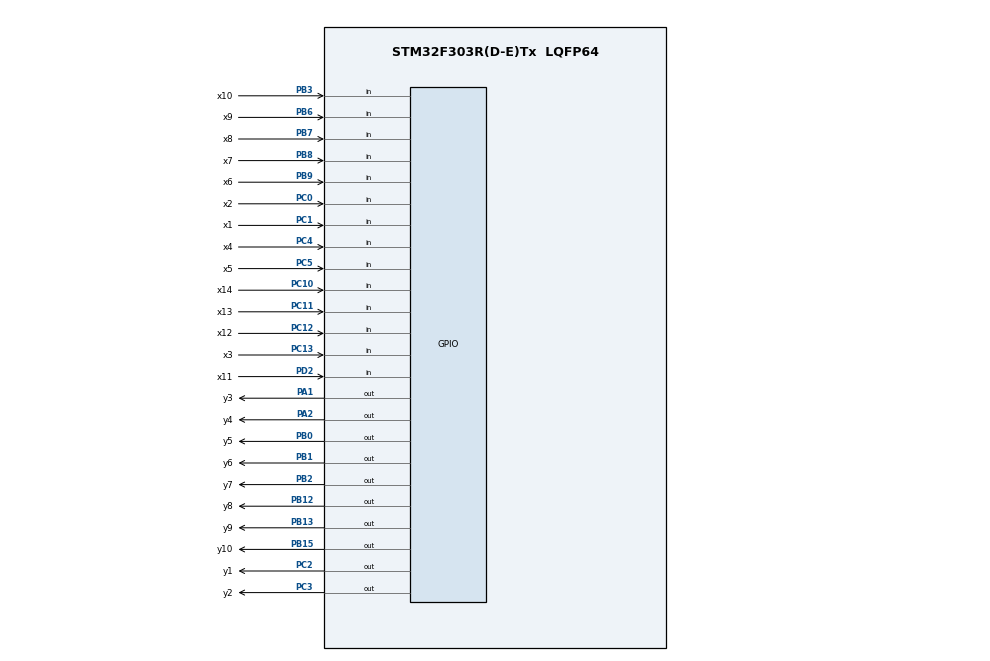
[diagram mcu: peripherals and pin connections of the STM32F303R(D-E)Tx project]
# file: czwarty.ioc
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Mcu.Family=STM32F3
Mcu.Name=STM32F303R(D-E)Tx
Mcu.Package=LQFP64
NVIC.PriorityGroup=NVIC_PRIORITYGROUP_4
PA0.Signal=S_TIM2_CH1_ETR
PA1.GPIO_Label=y3
PA1.Signal=GPIO_Output
PA2.GPIO_Label=y4
PA2.Signal=GPIO_Output
PB0.GPIO_Label=y5
PB0.Signal=GPIO_Output
PB1.GPIO_Label=y6
PB1.Signal=GPIO_Output
PB12.GPIO_Label=y8
PB12.Signal=GPIO_Output
PB13.GPIO_Label=y9
PB13.Signal=GPIO_Output
PB15.GPIO_Label=y10
PB15.Signal=GPIO_Output
PB2.GPIO_Label=y7
PB2.Signal=GPIO_Output
PB3.GPIO_Label=x10
PB3.Signal=GPIO_Input
PB4.Signal=S_TIM16_CH1
PB5.Signal=S_TIM17_CH1
PB6.GPIO_Label=x9
PB6.Signal=GPIO_Input
PB7.GPIO_Label=x8
PB7.Signal=GPIO_Input
PB8.GPIO_Label=x7
PB8.Signal=GPIO_Input
PB9.GPIO_Label=x6
PB9.Signal=GPIO_Input
PC0.GPIO_Label=x2
PC0.Signal=GPIO_Input
PC1.GPIO_Label=x1
PC1.Signal=GPIO_Input
PC10.GPIO_Label=x14
PC10.Signal=GPIO_Input
PC11.GPIO_Label=x13
PC11.Signal=GPIO_Input
PC12.GPIO_Label=x12
PC12.Signal=GPIO_Input
PC13.GPIO_Label=x3
PC13.Signal=GPIO_Input
PC14-OSC32_IN.Mode=LSE-External-Oscillator
PC14-OSC32_IN.Signal=RCC_OSC32_IN
PC15-OSC32_OUT.Mode=LSE-External-Oscillator
PC15-OSC32_OUT.Signal=RCC_OSC32_OUT
PC2.GPIO_Label=y1
PC2.Signal=GPIO_Output
PC3.GPIO_Label=y2
PC3.Signal=GPIO_Output
PC4.GPIO_Label=x4
PC4.Signal=GPIO_Input
PC5.GPIO_Label=x5
PC5.Signal=GPIO_Input
PC8.Signal=S_TIM8_CH3
PD2.GPIO_Label=x11
PD2.Signal=GPIO_Input
PF0-OSC_IN.Mode=HSE-External-Oscillator
PF0-OSC_IN.Signal=RCC_OSC_IN
PF1-OSC_OUT.Mode=HSE-External-Oscillator
PF1-OSC_OUT.Signal=RCC_OSC_OUT
ProjectManager.HeapSize=0x200
ProjectManager.StackSize=0x400
ProjectManager.TargetToolchain=TrueSTUDIO
RCC.AHBFreq_Value=72000000
RCC.APB1CLKDivider=RCC_HCLK_DIV2
RCC.APB1Freq_Value=36000000
RCC.APB1TimFreq_Value=72000000
RCC.APB2Freq_Value=72000000
RCC.APB2TimFreq_Value=72000000
RCC.CortexFreq_Value=72000000
RCC.HCLKFreq_Value=72000000
RCC.HSE_VALUE=8000000
RCC.HSI_VALUE=8000000
RCC.PLLMUL=RCC_PLL_MUL9
RCC.PLLSourceVirtual=RCC_PLLSOURCE_HSE
RCC.SYSCLKFreq_VALUE=72000000
RCC.SYSCLKSourceVirtual=RCC_SYSCLKSOURCE_PLLCLK
RCC.USBFreq_Value=72000000
SH.S_TIM16_CH1.0=TIM16_CH1
SH.S_TIM17_CH1.0=TIM17_CH1
SH.S_TIM2_CH1_ETR.0=TIM2_CH1
SH.S_TIM8_CH3.0=TIM8_CH3
board=czwarty

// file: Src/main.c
/**
  ******************************************************************************
  * @file           : main.c
  * @brief          : Main program body
  ******************************************************************************
  ** This notice applies to any and all portions of this file
  * that are not between comment pairs USER CODE BEGIN and
  * USER CODE END. Other portions of this file, whether
  * inserted by the user or by software development tools
  * are owned by their respective copyright owners.
  *
  * COPYRIGHT(c) 2019 STMicroelectronics
  *
  * Redistribution and use in source and binary forms, with or without modification,
  * are permitted provided that the following conditions are met:
  *   1. Redistributions of source code must retain the above copyright notice,
  *      this list of conditions and the following disclaimer.
  *   2. Redistributions in binary form must reproduce the above copyright notice,
  *      this list of conditions and the following disclaimer in the documentation
  *      and/or other materials provided with the distribution.
  *   3. Neither the name of STMicroelectronics nor the names of its contributors
  *      may be used to endorse or promote products derived from this software
  *      without specific prior written permission.
  *
  * THIS SOFTWARE IS PROVIDED BY THE COPYRIGHT HOLDERS AND CONTRIBUTORS "AS IS"
  * AND ANY EXPRESS OR IMPLIED WARRANTIES, INCLUDING, BUT NOT LIMITED TO, THE
  * IMPLIED WARRANTIES OF MERCHANTABILITY AND FITNESS FOR A PARTICULAR PURPOSE ARE
  * DISCLAIMED. IN NO EVENT SHALL THE COPYRIGHT HOLDER OR CONTRIBUTORS BE LIABLE
  * FOR ANY DIRECT, INDIRECT, INCIDENTAL, SPECIAL, EXEMPLARY, OR CONSEQUENTIAL
  * DAMAGES (INCLUDING, BUT NOT LIMITED TO, PROCUREMENT OF SUBSTITUTE GOODS OR
  * SERVICES; LOSS OF USE, DATA, OR PROFITS; OR BUSINESS INTERRUPTION) HOWEVER
  * CAUSED AND ON ANY THEORY OF LIABILITY, WHETHER IN CONTRACT, STRICT LIABILITY,
  * OR TORT (INCLUDING NEGLIGENCE OR OTHERWISE) ARISING IN ANY WAY OUT OF THE USE
  * OF THIS SOFTWARE, EVEN IF ADVISED OF THE POSSIBILITY OF SUCH DAMAGE.
  *
  ******************************************************************************
  */
#include "main.h"

/* USER CODE BEGIN PV */
/* Private variables ---------------------------------------------------------*/

/* USER CODE END PV */

static void LL_Init(void);
void SystemClock_Config(void);
static void MX_GPIO_Init(void);

/* USER CODE BEGIN PFP */
/* Private function prototypes -----------------------------------------------*/

/* USER CODE END PFP */

int main(void)
{

  /* MCU Configuration----------------------------------------------------------*/

  /* Reset of all peripherals, Initializes the Flash interface and the Systick. */
  LL_Init();

  /* Configure the system clock */
  SystemClock_Config();

  /* Initialize all configured peripherals */
  MX_GPIO_Init();

  /* Infinite loop */
  while (1)
  {

  /* USER CODE BEGIN 3 */
	  LL_GPIO_SetOutputPin(y1_GPIO_Port,y1_Pin);// zapalenie diody
	  LL_GPIO_SetOutputPin(y2_GPIO_Port,y2_Pin);
	          //delay(400);
	           //LL_GPIO_ResetOutputPin(y9_GPIO_Port,y9_Pin); // zgaszenie diody
	          //Delay(400);

  }
  /* USER CODE END 3 */

}

static void LL_Init(void)
{

  LL_APB2_GRP1_EnableClock(LL_APB2_GRP1_PERIPH_SYSCFG);

  NVIC_SetPriorityGrouping(NVIC_PRIORITYGROUP_4);

  /* System interrupt init*/
  /* MemoryManagement_IRQn interrupt configuration */
  NVIC_SetPriority(MemoryManagement_IRQn, NVIC_EncodePriority(NVIC_GetPriorityGrouping(),0, 0));
  /* BusFault_IRQn interrupt configuration */
  NVIC_SetPriority(BusFault_IRQn, NVIC_EncodePriority(NVIC_GetPriorityGrouping(),0, 0));
  /* UsageFault_IRQn interrupt configuration */
  NVIC_SetPriority(UsageFault_IRQn, NVIC_EncodePriority(NVIC_GetPriorityGrouping(),0, 0));
  /* SVCall_IRQn interrupt configuration */
  NVIC_SetPriority(SVCall_IRQn, NVIC_EncodePriority(NVIC_GetPriorityGrouping(),0, 0));
  /* DebugMonitor_IRQn interrupt configuration */
  NVIC_SetPriority(DebugMonitor_IRQn, NVIC_EncodePriority(NVIC_GetPriorityGrouping(),0, 0));
  /* PendSV_IRQn interrupt configuration */
  NVIC_SetPriority(PendSV_IRQn, NVIC_EncodePriority(NVIC_GetPriorityGrouping(),0, 0));
  /* SysTick_IRQn interrupt configuration */
  NVIC_SetPriority(SysTick_IRQn, NVIC_EncodePriority(NVIC_GetPriorityGrouping(),0, 0));

}

void SystemClock_Config(void)
{

  LL_FLASH_SetLatency(LL_FLASH_LATENCY_2);

   if(LL_FLASH_GetLatency() != LL_FLASH_LATENCY_2)
  {
  Error_Handler();
  }
  LL_RCC_HSE_Enable();

   /* Wait till HSE is ready */
  while(LL_RCC_HSE_IsReady() != 1)
  {

  }
  LL_RCC_PLL_ConfigDomain_SYS(LL_RCC_PLLSOURCE_HSE, LL_RCC_PLL_MUL_9, LL_RCC_PREDIV_DIV_1);

  LL_RCC_PLL_Enable();

   /* Wait till PLL is ready */
  while(LL_RCC_PLL_IsReady() != 1)
  {

  }
  LL_RCC_SetAHBPrescaler(LL_RCC_SYSCLK_DIV_1);

  LL_RCC_SetAPB1Prescaler(LL_RCC_APB1_DIV_2);

  LL_RCC_SetAPB2Prescaler(LL_RCC_APB1_DIV_1);

  LL_RCC_SetSysClkSource(LL_RCC_SYS_CLKSOURCE_PLL);

   /* Wait till System clock is ready */
  while(LL_RCC_GetSysClkSource() != LL_RCC_SYS_CLKSOURCE_STATUS_PLL)
  {

  }
  LL_Init1msTick(72000000);

  LL_SYSTICK_SetClkSource(LL_SYSTICK_CLKSOURCE_HCLK);

  LL_SetSystemCoreClock(72000000);

  /* SysTick_IRQn interrupt configuration */
  NVIC_SetPriority(SysTick_IRQn, NVIC_EncodePriority(NVIC_GetPriorityGrouping(),0, 0));
}

/** Configure pins as
        * Analog
        * Input
        * Output
        * EVENT_OUT
        * EXTI
     PA0   ------> S_TIM2_CH1_ETR
     PC8   ------> S_TIM8_CH3
     PB4   ------> S_TIM16_CH1
     PB5   ------> S_TIM17_CH1
*/
static void MX_GPIO_Init(void)
{

  LL_GPIO_InitTypeDef GPIO_InitStruct;

  /* GPIO Ports Clock Enable */
  LL_AHB1_GRP1_EnableClock(LL_AHB1_GRP1_PERIPH_GPIOC);
  LL_AHB1_GRP1_EnableClock(LL_AHB1_GRP1_PERIPH_GPIOF);
  LL_AHB1_GRP1_EnableClock(LL_AHB1_GRP1_PERIPH_GPIOA);
  LL_AHB1_GRP1_EnableClock(LL_AHB1_GRP1_PERIPH_GPIOB);
  LL_AHB1_GRP1_EnableClock(LL_AHB1_GRP1_PERIPH_GPIOD);

  /**/
  LL_GPIO_ResetOutputPin(GPIOC, y1_Pin|y2_Pin);

  /**/
  LL_GPIO_ResetOutputPin(GPIOA, y3_Pin|y4_Pin);

  /**/
  LL_GPIO_ResetOutputPin(GPIOB, y5_Pin|y6_Pin|y7_Pin|y8_Pin
                          |y9_Pin|y10_Pin);

  /**/
  GPIO_InitStruct.Pin = x3_Pin|x2_Pin|x1_Pin|x4_Pin
                          |x5_Pin|x14_Pin|x13_Pin|x12_Pin;
  GPIO_InitStruct.Mode = LL_GPIO_MODE_INPUT;
  GPIO_InitStruct.Pull = LL_GPIO_PULL_NO;
  LL_GPIO_Init(GPIOC, &GPIO_InitStruct);

  /**/
  GPIO_InitStruct.Pin = y1_Pin|y2_Pin;
  GPIO_InitStruct.Mode = LL_GPIO_MODE_OUTPUT;
  GPIO_InitStruct.Speed = LL_GPIO_SPEED_FREQ_LOW;
  GPIO_InitStruct.OutputType = LL_GPIO_OUTPUT_PUSHPULL;
  GPIO_InitStruct.Pull = LL_GPIO_PULL_NO;
  LL_GPIO_Init(GPIOC, &GPIO_InitStruct);

  /**/
  GPIO_InitStruct.Pin = LL_GPIO_PIN_0;
  GPIO_InitStruct.Mode = LL_GPIO_MODE_ALTERNATE;
  GPIO_InitStruct.Speed = LL_GPIO_SPEED_FREQ_LOW;
  GPIO_InitStruct.OutputType = LL_GPIO_OUTPUT_PUSHPULL;
  GPIO_InitStruct.Pull = LL_GPIO_PULL_NO;
  GPIO_InitStruct.Alternate = LL_GPIO_AF_1;
  LL_GPIO_Init(GPIOA, &GPIO_InitStruct);

  /**/
  GPIO_InitStruct.Pin = y3_Pin|y4_Pin;
  GPIO_InitStruct.Mode = LL_GPIO_MODE_OUTPUT;
  GPIO_InitStruct.Speed = LL_GPIO_SPEED_FREQ_LOW;
  GPIO_InitStruct.OutputType = LL_GPIO_OUTPUT_PUSHPULL;
  GPIO_InitStruct.Pull = LL_GPIO_PULL_NO;
  LL_GPIO_Init(GPIOA, &GPIO_InitStruct);

  /**/
  GPIO_InitStruct.Pin = y5_Pin|y6_Pin|y7_Pin|y8_Pin
                          |y9_Pin|y10_Pin;
  GPIO_InitStruct.Mode = LL_GPIO_MODE_OUTPUT;
  GPIO_InitStruct.Speed = LL_GPIO_SPEED_FREQ_LOW;
  GPIO_InitStruct.OutputType = LL_GPIO_OUTPUT_PUSHPULL;
  GPIO_InitStruct.Pull = LL_GPIO_PULL_NO;
  LL_GPIO_Init(GPIOB, &GPIO_InitStruct);

  /**/
  GPIO_InitStruct.Pin = LL_GPIO_PIN_8;
  GPIO_InitStruct.Mode = LL_GPIO_MODE_ALTERNATE;
  GPIO_InitStruct.Speed = LL_GPIO_SPEED_FREQ_LOW;
  GPIO_InitStruct.OutputType = LL_GPIO_OUTPUT_PUSHPULL;
  GPIO_InitStruct.Pull = LL_GPIO_PULL_NO;
  GPIO_InitStruct.Alternate = LL_GPIO_AF_4;
  LL_GPIO_Init(GPIOC, &GPIO_InitStruct);

  /**/
  GPIO_InitStruct.Pin = x11_Pin;
  GPIO_InitStruct.Mode = LL_GPIO_MODE_INPUT;
  GPIO_InitStruct.Pull = LL_GPIO_PULL_NO;
  LL_GPIO_Init(x11_GPIO_Port, &GPIO_InitStruct);

  /**/
  GPIO_InitStruct.Pin = x10_Pin|x9_Pin|x8_Pin|x7_Pin
                          |x6_Pin;
  GPIO_InitStruct.Mode = LL_GPIO_MODE_INPUT;
  GPIO_InitStruct.Pull = LL_GPIO_PULL_NO;
  LL_GPIO_Init(GPIOB, &GPIO_InitStruct);

  /**/
  GPIO_InitStruct.Pin = LL_GPIO_PIN_4;
  GPIO_InitStruct.Mode = LL_GPIO_MODE_ALTERNATE;
  GPIO_InitStruct.Speed = LL_GPIO_SPEED_FREQ_LOW;
  GPIO_InitStruct.OutputType = LL_GPIO_OUTPUT_PUSHPULL;
  GPIO_InitStruct.Pull = LL_GPIO_PULL_NO;
  GPIO_InitStruct.Alternate = LL_GPIO_AF_1;
  LL_GPIO_Init(GPIOB, &GPIO_InitStruct);

  /**/
  GPIO_InitStruct.Pin = LL_GPIO_PIN_5;
  GPIO_InitStruct.Mode = LL_GPIO_MODE_ALTERNATE;
  GPIO_InitStruct.Speed = LL_GPIO_SPEED_FREQ_LOW;
  GPIO_InitStruct.OutputType = LL_GPIO_OUTPUT_PUSHPULL;
  GPIO_InitStruct.Pull = LL_GPIO_PULL_NO;
  GPIO_InitStruct.Alternate = LL_GPIO_AF_10;
  LL_GPIO_Init(GPIOB, &GPIO_InitStruct);

}

void _Error_Handler(char *file, int line)
{
  while(1)
  {
  }
}

/************************ (C) COPYRIGHT STMicroelectronics *****END OF FILE****/
